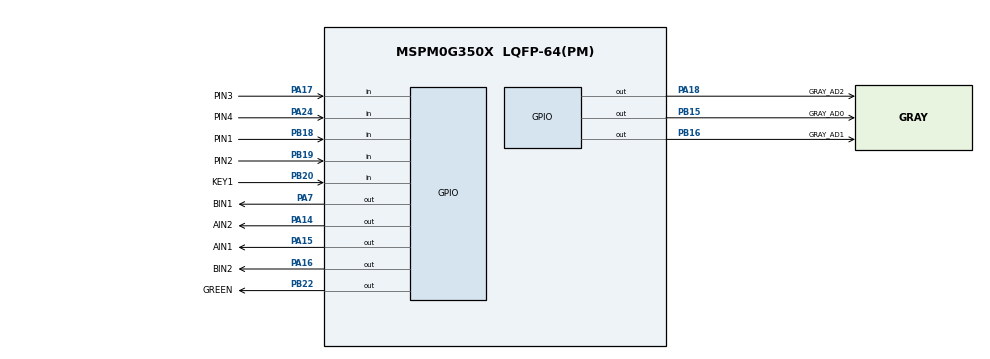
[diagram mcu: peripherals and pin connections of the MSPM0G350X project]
/**
 * @cliArgs --device "MSPM0G350X" --part "Default" --package "LQFP-64(PM)" --product "mspm0_sdk@2.05.01.01"
 * @versions {"tool":"1.24.1+4189"}
 */

/**
 * Import the modules used in this configuration.
 */
const ADC12  = scripting.addModule("/ti/driverlib/ADC12", {}, false);
const ADC121 = ADC12.addInstance();
const ADC122 = ADC12.addInstance();
const GPIO   = scripting.addModule("/ti/driverlib/GPIO", {}, false);
const GPIO1  = GPIO.addInstance();
const GPIO2  = GPIO.addInstance();
const GPIO3  = GPIO.addInstance();
const GPIO4  = GPIO.addInstance();
const GPIO5  = GPIO.addInstance();
const GPIO6  = GPIO.addInstance();
const GPIO7  = GPIO.addInstance();
const I2C    = scripting.addModule("/ti/driverlib/I2C", {}, false);
const I2C1   = I2C.addInstance();
const PWM    = scripting.addModule("/ti/driverlib/PWM", {}, false);
const PWM1   = PWM.addInstance();
const SYSCTL = scripting.addModule("/ti/driverlib/SYSCTL");
const TIMER  = scripting.addModule("/ti/driverlib/TIMER", {}, false);
const TIMER1 = TIMER.addInstance();
const TIMER2 = TIMER.addInstance();
const TIMER3 = TIMER.addInstance();

/**
 * Write custom configuration values to the imported modules.
 */
const divider9       = system.clockTree["UDIV"];
divider9.divideValue = 2;

const multiplier2         = system.clockTree["PLL_QDIV"];
multiplier2.multiplyValue = 4;

const mux4       = system.clockTree["EXHFMUX"];
mux4.inputSelect = "EXHFMUX_XTAL";

const mux5       = system.clockTree["EXLFMUX"];
mux5.inputSelect = "EXLFMUX_XTAL";

const mux8       = system.clockTree["HSCLKMUX"];
mux8.inputSelect = "HSCLKMUX_SYSPLL0";

const mux12       = system.clockTree["SYSPLLMUX"];
mux12.inputSelect = "zSYSPLLMUX_HFCLK";

const pinFunction4        = system.clockTree["HFXT"];
pinFunction4.enable       = true;
pinFunction4.inputFreq    = 40;
pinFunction4.HFXTStartup  = 10;
pinFunction4.HFCLKMonitor = true;

ADC121.sampClkDiv                        = "DL_ADC12_CLOCK_DIVIDE_8";
ADC121.$name                             = "ADC_VOLTAGE";
ADC121.powerDownMode                     = "DL_ADC12_POWER_DOWN_MODE_MANUAL";
ADC121.adcPin0Config.hideOutputInversion = scripting.forceWrite(false);
ADC121.adcPin0Config.$name               = "ti_driverlib_gpio_GPIOPinGeneric2";

ADC122.$name               = "GRAY_OUT";
ADC122.adcMem0chansel      = "DL_ADC12_INPUT_CHAN_4";
ADC122.adcMem0_name        = "ADC_CH4";
ADC122.sampClkDiv          = "DL_ADC12_CLOCK_DIVIDE_8";
ADC122.powerDownMode       = "DL_ADC12_POWER_DOWN_MODE_MANUAL";
ADC122.sampleTime0         = "40000ns";
ADC122.sampleTime1         = "40000ns";
ADC122.adcPin4Config.$name = "ti_driverlib_gpio_GPIOPinGeneric6";

const Board = scripting.addModule("/ti/driverlib/Board", {}, false);

GPIO1.$name                         = "USERLED";
GPIO1.associatedPins[0].$name       = "GREEN";
GPIO1.associatedPins[0].pin.$assign = "PB22";

GPIO2.$name                         = "OLED";
GPIO2.port                          = "PORTB";
GPIO2.associatedPins.create(2);
GPIO2.associatedPins[0].$name       = "SCL";
GPIO2.associatedPins[0].assignedPin = "9";
GPIO2.associatedPins[1].$name       = "SDA";
GPIO2.associatedPins[1].assignedPin = "8";

GPIO3.$name                         = "KEY";
GPIO3.port                          = "PORTB";
GPIO3.associatedPins.create(3);
GPIO3.associatedPins[0].$name       = "KEY1";
GPIO3.associatedPins[0].direction   = "INPUT";
GPIO3.associatedPins[0].assignedPin = "20";
GPIO3.associatedPins[0].pin.$assign = "PB20";
GPIO3.associatedPins[1].$name       = "KEY2";
GPIO3.associatedPins[1].assignedPin = "21";
GPIO3.associatedPins[1].direction   = "INPUT";
GPIO3.associatedPins[2].direction   = "INPUT";
GPIO3.associatedPins[2].assignedPin = "14";
GPIO3.associatedPins[2].$name       = "KEY4";

GPIO4.$name                         = "TB6612";
GPIO4.associatedPins.create(4);
GPIO4.associatedPins[0].$name       = "AIN1";
GPIO4.associatedPins[0].pin.$assign = "PA15";
GPIO4.associatedPins[1].$name       = "AIN2";
GPIO4.associatedPins[1].pin.$assign = "PA14";
GPIO4.associatedPins[2].$name       = "BIN1";
GPIO4.associatedPins[2].pin.$assign = "PA7";
GPIO4.associatedPins[3].$name       = "BIN2";
GPIO4.associatedPins[3].pin.$assign = "PA16";

GPIO5.$name                               = "EncoderA";
GPIO5.associatedPins.create(2);
GPIO5.associatedPins[0].$name             = "PIN1";
GPIO5.associatedPins[0].direction         = "INPUT";
GPIO5.associatedPins[0].interruptEn       = true;
GPIO5.associatedPins[0].polarity          = "RISE";
GPIO5.associatedPins[0].interruptPriority = "2";
GPIO5.associatedPins[0].pin.$assign       = "PB18";
GPIO5.associatedPins[1].$name             = "PIN2";
GPIO5.associatedPins[1].direction         = "INPUT";
GPIO5.associatedPins[1].pin.$assign       = "PB19";

GPIO6.$name                               = "EncoderB";
GPIO6.associatedPins.create(2);
GPIO6.associatedPins[0].$name             = "PIN3";
GPIO6.associatedPins[0].direction         = "INPUT";
GPIO6.associatedPins[0].interruptEn       = true;
GPIO6.associatedPins[0].polarity          = "RISE";
GPIO6.associatedPins[0].interruptPriority = "2";
GPIO6.associatedPins[0].pin.$assign       = "PA17";
GPIO6.associatedPins[1].$name             = "PIN4";
GPIO6.associatedPins[1].direction         = "INPUT";
GPIO6.associatedPins[1].pin.$assign       = "PA24";

GPIO7.$name                         = "ganwei_huidu";
GPIO7.associatedPins.create(3);
GPIO7.associatedPins[0].$name       = "GRAY_AD0";
GPIO7.associatedPins[0].pin.$assign = "PB15";
GPIO7.associatedPins[1].$name       = "GRAY_AD1";
GPIO7.associatedPins[1].pin.$assign = "PB16";
GPIO7.associatedPins[2].$name       = "GRAY_AD2";
GPIO7.associatedPins[2].pin.$assign = "PA18";

I2C1.$name              = "I2C_0";
I2C1.sdaPinConfig.$name = "ti_driverlib_gpio_GPIOPinGeneric0";
I2C1.sclPinConfig.$name = "ti_driverlib_gpio_GPIOPinGeneric1";

PWM1.$name                              = "PWM";
PWM1.timerStartTimer                    = true;
PWM1.clockDivider                       = 8;
PWM1.pwmMode                            = "EDGE_ALIGN_UP";
PWM1.peripheral.$assign                 = "TIMG0";
PWM1.PWM_CHANNEL_0.$name                = "ti_driverlib_pwm_PWMTimerCC0";
PWM1.PWM_CHANNEL_0.dutyCycle            = 5;
PWM1.PWM_CHANNEL_1.$name                = "ti_driverlib_pwm_PWMTimerCC1";
PWM1.PWM_CHANNEL_1.dutyCycle            = 5;
PWM1.ccp0PinConfig.$name                = "ti_driverlib_gpio_GPIOPinGeneric4";
PWM1.ccp0PinConfig.direction            = scripting.forceWrite("OUTPUT");
PWM1.ccp0PinConfig.hideOutputInversion  = scripting.forceWrite(false);
PWM1.ccp0PinConfig.onlyInternalResistor = scripting.forceWrite(false);
PWM1.ccp0PinConfig.passedPeripheralType = scripting.forceWrite("Digital");
PWM1.ccp1PinConfig.$name                = "ti_driverlib_gpio_GPIOPinGeneric5";
PWM1.ccp1PinConfig.direction            = scripting.forceWrite("OUTPUT");
PWM1.ccp1PinConfig.hideOutputInversion  = scripting.forceWrite(false);
PWM1.ccp1PinConfig.onlyInternalResistor = scripting.forceWrite(false);
PWM1.ccp1PinConfig.passedPeripheralType = scripting.forceWrite("Digital");

SYSCTL.forceDefaultClkConfig = true;
SYSCTL.clockTreeEn           = true;

TIMER1.$name              = "TIME_End";
TIMER1.interrupts         = ["ZERO"];
TIMER1.timerClkDiv        = 8;
TIMER1.timerStartTimer    = true;
TIMER1.timerMode          = "PERIODIC";
TIMER1.timerClkPrescale   = 20;
TIMER1.timerPeriod        = "20 ms";
TIMER1.interruptPriority  = "2";
TIMER1.peripheral.$assign = "TIMG6";

TIMER2.$name              = "Huidu_Time";
TIMER2.timerClkDiv        = 8;
TIMER2.timerClkPrescale   = 10;
TIMER2.interrupts         = ["ZERO"];
TIMER2.timerStartTimer    = true;
TIMER2.timerMode          = "PERIODIC";
TIMER2.timerPeriod        = "20 ms";
TIMER2.interruptPriority  = "3";
TIMER2.peripheral.$assign = "TIMG7";

TIMER3.$name              = "Pid_Time";
TIMER3.timerClkDiv        = 8;
TIMER3.interrupts         = ["ZERO"];
TIMER3.timerMode          = "PERIODIC";
TIMER3.timerStartTimer    = true;
TIMER3.timerPeriod        = "20ms";
TIMER3.timerClkPrescale   = 100;
TIMER3.interruptPriority  = "1";
TIMER3.peripheral.$assign = "TIMG8";

/**
 * Pinmux solution for unlocked pins/peripherals. This ensures that minor changes to the automatic solver in a future
 * version of the tool will not impact the pinmux you originally saw.  These lines can be completely deleted in order to
 * re-solve from scratch.
 */
pinFunction4.peripheral.$suggestSolution           = "SYSCTL";
pinFunction4.peripheral.hfxInPin.$suggestSolution  = "PA5";
pinFunction4.peripheral.hfxOutPin.$suggestSolution = "PA6";
ADC121.peripheral.$suggestSolution                 = "ADC0";
ADC121.peripheral.adcPin0.$suggestSolution         = "PA27";
ADC122.peripheral.$suggestSolution                 = "ADC1";
ADC122.peripheral.adcPin4.$suggestSolution         = "PB17";
Board.peripheral.$suggestSolution                  = "DEBUGSS";
Board.peripheral.swclkPin.$suggestSolution         = "PA20";
Board.peripheral.swdioPin.$suggestSolution         = "PA19";
GPIO2.associatedPins[0].pin.$suggestSolution       = "PB9";
GPIO2.associatedPins[1].pin.$suggestSolution       = "PB8";
GPIO3.associatedPins[1].pin.$suggestSolution       = "PB21";
GPIO3.associatedPins[2].pin.$suggestSolution       = "PB14";
I2C1.peripheral.$suggestSolution                   = "I2C0";
I2C1.peripheral.sdaPin.$suggestSolution            = "PA0";
I2C1.peripheral.sclPin.$suggestSolution            = "PA1";
PWM1.peripheral.ccp0Pin.$suggestSolution           = "PA12";
PWM1.peripheral.ccp1Pin.$suggestSolution           = "PA13";
